AUTOSAR XML (schema 00050)
package /ComponentTypes
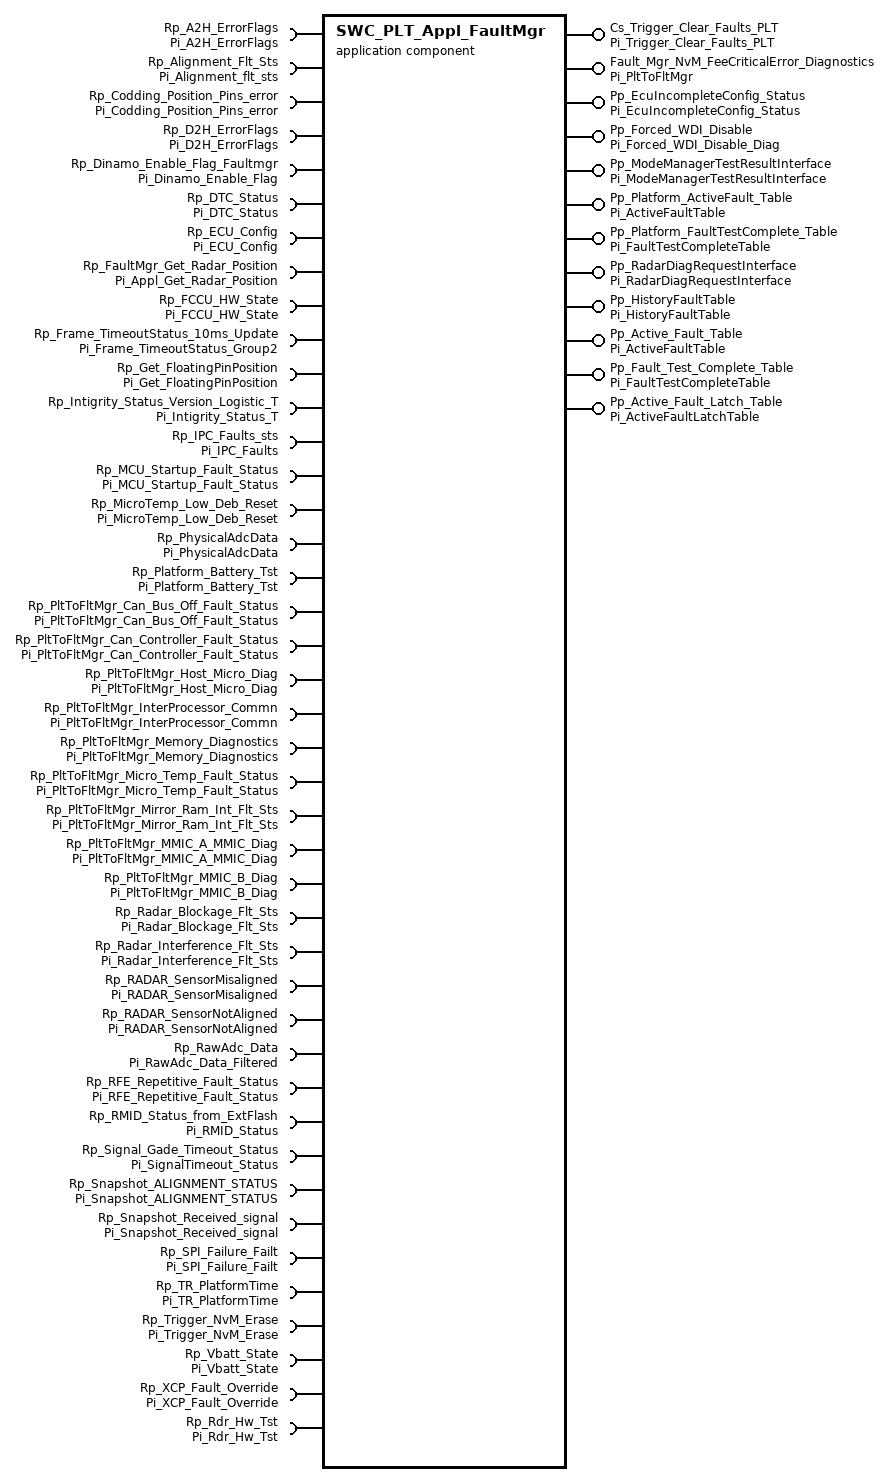
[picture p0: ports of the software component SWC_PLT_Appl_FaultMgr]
  application sw component type SWC_PLT_Appl_FaultMgr
    8 x provide port:
      Cs_Trigger_Clear_Faults_PLT: server-com-spec{operation=Operation, queue-length=1}, provided-interface=Pi_Trigger_Clear_Faults_PLT
      Fault_Mgr_NvM_FeeCriticalError_Diagnostics: server-com-spec{operation=PltToFltMgr_NvM_FeeCriticalError_Diagnostics, queue-length=1}, provided-interface=Pi_PltToFltMgr
      Pp_EcuIncompleteConfig_Status: nonqueued-sender-com-spec{data-element=De_EcuIncompleteConfig_Status, init-value=85}, provided-interface=Pi_EcuIncompleteConfig_Status
      Pp_Forced_WDI_Disable: nonqueued-sender-com-spec{data-element=Forced_WDI_Disable, init-value=0}, provided-interface=Pi_Forced_WDI_Disable_Diag
      Pp_ModeManagerTestResultInterface: nonqueued-sender-com-spec=De_TR_ModeManager, provided-interface=Pi_ModeManagerTestResultInterface
      Pp_Platform_ActiveFault_Table: nonqueued-sender-com-spec{data-element=De_ActiveFaultTable, init-value=constant-reference=C_Fault_T}, provided-interface=Pi_ActiveFaultTable
      Pp_Platform_FaultTestComplete_Table: nonqueued-sender-com-spec{data-element=De_FaultTestCompleteTable, init-value=constant-reference=C_Fault_T}, provided-interface=Pi_FaultTestCompleteTable
      Pp_RadarDiagRequestInterface: nonqueued-sender-com-spec{data-element=De_RadarDiagRequest, init-value=constant-reference=C_RadarDiagRequest_T}, provided-interface=Pi_RadarDiagRequestInterface
    41 x require port:
      Rp_A2H_ErrorFlags: nonqueued-receiver-com-spec{data-element=De_A2H_ErrorFlags, filter=data-filter-type=ALWAYS, init-value=constant-reference=C_A2H_ErrorFlags}, required-interface=Pi_A2H_ErrorFlags
      Rp_Alignment_Flt_Sts: nonqueued-receiver-com-spec{data-element=De_PltToFltMgr_Alignment_Faults, filter=data-filter-type=ALWAYS, init-value=constant-reference=C_PltToFltMgr_Alignment_Faults}, required-interface=Pi_Alignment_flt_sts
      Rp_Codding_Position_Pins_error: nonqueued-receiver-com-spec{data-element=Codding_Position_Pins_error, filter=data-filter-type=ALWAYS, init-value=0}, required-interface=Pi_Codding_Position_Pins_error
      Rp_D2H_ErrorFlags: nonqueued-receiver-com-spec{data-element=De_D2H_ErrorFlags, filter=data-filter-type=ALWAYS, init-value=constant-reference=C_D2H_ErrorFlags}, required-interface=Pi_D2H_ErrorFlags
      Rp_Dinamo_Enable_Flag_Faultmgr: nonqueued-receiver-com-spec{data-element=De_Dinamo_Enable_Flag, filter=data-filter-type=ALWAYS, init-value=85}, required-interface=Pi_Dinamo_Enable_Flag
      Rp_DTC_Status: nonqueued-receiver-com-spec{data-element=De_DTC_Status, filter=data-filter-type=ALWAYS, init-value=0}, required-interface=Pi_DTC_Status
      Rp_ECU_Config: nonqueued-receiver-com-spec{data-element=Dt_ECU_Config, filter=data-filter-type=ALWAYS, init-value=fields=[ECU_Incomplete_Config_Status:0, ECU_Configuration_Updated_Status:0]}, required-interface=Pi_ECU_Config
      Rp_FaultMgr_Get_Radar_Position: nonqueued-receiver-com-spec{data-element=De_ECUPosition, filter=data-filter-type=ALWAYS, init-value=0}, required-interface=Pi_Appl_Get_Radar_Position
      Rp_FCCU_HW_State: nonqueued-receiver-com-spec{data-element=FCCU_HW_State, filter=data-filter-type=ALWAYS, init-value=0}, required-interface=Pi_FCCU_HW_State
      Rp_Frame_TimeoutStatus_10ms_Update: nonqueued-receiver-com-spec{data-element=TimeoutStatus_Group2, filter=data-filter-type=ALWAYS, init-value=constant-reference=C_SignalTimeoutStatus_Group2_T}, required-interface=Pi_Frame_TimeoutStatus_Group2
      Rp_Get_FloatingPinPosition: client-com-spec=FaultStatus, required-interface=Pi_Get_FloatingPinPosition
      Rp_Intigrity_Status_Version_Logistic_T: nonqueued-receiver-com-spec{data-element=Dt_Intigrity_Status_T, filter=data-filter-type=ALWAYS, init-value=0}, required-interface=Pi_Intigrity_Status_T
      Rp_IPC_Faults_sts: nonqueued-receiver-com-spec{data-element=De_IPC_Faults, filter=data-filter-type=ALWAYS, init-value=fields=[IPC_M2D_Crc_Err_Cnt:0, IPC_D2M_Crc_Err_Cnt:0, IPC_D2A_Crc_Err_Cnt:0, IPC_A2M_Crc_Err_Cnt:0]}, required-interface=Pi_IPC_Faults
      Rp_MCU_Startup_Fault_Status: nonqueued-receiver-com-spec{data-element=MCU_Startup_Fault_Status, filter=data-filter-type=ALWAYS, init-value=fields=[Mcu_Startup_Fault_Status:0, Mcu_Repetitive_Reset_Fault_Status:0]}, required-interface=Pi_MCU_Startup_Fault_Status
      Rp_MicroTemp_Low_Deb_Reset: nonqueued-receiver-com-spec{data-element=De_MicroTemp_Low_Deb_Reset, filter=data-filter-type=ALWAYS, init-value=85}, required-interface=Pi_MicroTemp_Low_Deb_Reset
      Rp_PhysicalAdcData: nonqueued-receiver-com-spec{data-element=De_PhysicalAdcData, filter=data-filter-type=ALWAYS, init-value=fields=[Adc_Board_Rev:0, Adc_Batt_Volt:0, Adc_Pos_Gnd_A:0, Adc_Pos_Gnd_B:0, Adc_Pos_Gnd_C:0, Adc_Pos_Gnd_D:0, Adc_Eth_0v9:0, Adc_Rdi_Detect:0, Adc_MMIC_Temp:0, Adc_Mcu_Temp:0, Validity_Flag:0]}, required-interface=Pi_PhysicalAdcData
      Rp_Platform_Battery_Tst: nonqueued-receiver-com-spec{data-element=De_Platform_Battery_Tst, filter=data-filter-type=ALWAYS, init-value=constant-reference=C_Battery_Tst_T}, required-interface=Pi_Platform_Battery_Tst
      Rp_PltToFltMgr_Can_Bus_Off_Fault_Status: nonqueued-receiver-com-spec{data-element=De_PltToFltMgr_Can_Bus_Off_Fault_Status, filter=data-filter-type=ALWAYS, init-value=0}, required-interface=Pi_PltToFltMgr_Can_Bus_Off_Fault_Status
      Rp_PltToFltMgr_Can_Controller_Fault_Status: nonqueued-receiver-com-spec{data-element=De_PltToFltMgr_Can_Controller_Fault_Status, filter=data-filter-type=ALWAYS, init-value=0}, required-interface=Pi_PltToFltMgr_Can_Controller_Fault_Status
      Rp_PltToFltMgr_Host_Micro_Diag: nonqueued-receiver-com-spec{data-element=De_PltToFltMgr_Host_Micro_Diag, filter=data-filter-type=ALWAYS, init-value=constant-reference=C_VldtnToFltMgr_Host_Micro_Diag_T}, required-interface=Pi_PltToFltMgr_Host_Micro_Diag
      Rp_PltToFltMgr_InterProcessor_Commn: nonqueued-receiver-com-spec{data-element=De_PltToFltMgr_InterProcessor_Commn_T, filter=data-filter-type=ALWAYS, init-value=constant-reference=C_VldtnToFltMgr_InterProcessor_Commn_T}, required-interface=Pi_PltToFltMgr_InterProcessor_Commn
      Rp_PltToFltMgr_Memory_Diagnostics: nonqueued-receiver-com-spec{data-element=De_PltToFltMgr_Memory_Diagnostics, filter=data-filter-type=ALWAYS, init-value=constant-reference=C_VldtnToFltMgr_Memory_Diagnostics_T}, required-interface=Pi_PltToFltMgr_Memory_Diagnostics
      Rp_PltToFltMgr_Micro_Temp_Fault_Status: nonqueued-receiver-com-spec{data-element=De_PltToFltMgr_Micro_Temp_Fault_Status, filter=data-filter-type=ALWAYS, init-value=constant-reference=C_VldtnToFltMgr_Micro_Temp_Fault_Status_T}, required-interface=Pi_PltToFltMgr_Micro_Temp_Fault_Status
      Rp_PltToFltMgr_Mirror_Ram_Int_Flt_Sts: nonqueued-receiver-com-spec{data-element=PltToFltMgr_Mirror_Ram_Int_Flt_Sts, filter=data-filter-type=ALWAYS, init-value=0}, required-interface=Pi_PltToFltMgr_Mirror_Ram_Int_Flt_Sts
      Rp_PltToFltMgr_MMIC_A_MMIC_Diag: nonqueued-receiver-com-spec{data-element=De_PltToFltMgr_MMIC_A_MMIC_Diag_T, filter=data-filter-type=ALWAYS, init-value=constant-reference=C_VldtnToFltMgr_MMIC_A_MMIC_Diag_T}, required-interface=Pi_PltToFltMgr_MMIC_A_MMIC_Diag
      Rp_PltToFltMgr_MMIC_B_Diag: nonqueued-receiver-com-spec{data-element=De_PltToFltMgr_MMIC_B_Diag_T, filter=data-filter-type=ALWAYS, init-value=constant-reference=C_VldtnToFltMgr_MMIC_B_Diag_T}, required-interface=Pi_PltToFltMgr_MMIC_B_Diag
      Rp_Radar_Blockage_Flt_Sts: nonqueued-receiver-com-spec{data-element=De_Radar_Blockage_Flt_Sts, filter=data-filter-type=ALWAYS, init-value=constant-reference=C_VldtnToFltMgr_Blockage_Detection_T}, required-interface=Pi_Radar_Blockage_Flt_Sts
      Rp_Radar_Interference_Flt_Sts: nonqueued-receiver-com-spec{data-element=De_Radar_Interference_Flt_Sts, filter=data-filter-type=ALWAYS, init-value=0}, required-interface=Pi_Radar_Interference_Flt_Sts
      Rp_RADAR_SensorMisaligned: nonqueued-receiver-com-spec{data-element=RADAR_SensorMisaligned, filter=data-filter-type=ALWAYS, init-value=0}, required-interface=Pi_RADAR_SensorMisaligned
      Rp_RADAR_SensorNotAligned: nonqueued-receiver-com-spec{data-element=RADAR_SensorNotAligned, filter=data-filter-type=ALWAYS, init-value=0}, required-interface=Pi_RADAR_SensorNotAligned
      Rp_RawAdc_Data: nonqueued-receiver-com-spec{data-element=De_RawAdcData, filter=data-filter-type=ALWAYS, init-value=constant-reference=C_RawAdcDataFilt_T}, required-interface=Pi_RawAdc_Data_Filtered
      Rp_RFE_Repetitive_Fault_Status: nonqueued-receiver-com-spec{data-element=De_RFE_Repetitive_Fault_Status, filter=data-filter-type=ALWAYS, init-value=0}, required-interface=Pi_RFE_Repetitive_Fault_Status
      Rp_RMID_Status_from_ExtFlash: nonqueued-receiver-com-spec{data-element=RMID_Status, filter=data-filter-type=ALWAYS, init-value=0}, required-interface=Pi_RMID_Status
      Rp_Signal_Gade_Timeout_Status: nonqueued-receiver-com-spec{data-element=De_Status, filter=data-filter-type=ALWAYS, init-value=0}, required-interface=Pi_SignalTimeout_Status
      Rp_Snapshot_ALIGNMENT_STATUS: nonqueued-receiver-com-spec{data-element=De_Snapshot_ALIGNMENT_STATUS, filter=data-filter-type=ALWAYS, init-value=constant-reference=C_Snapshot_SupplierCode}, required-interface=Pi_Snapshot_ALIGNMENT_STATUS
      Rp_Snapshot_Received_signal: nonqueued-receiver-com-spec{data-element=De_SnapshotReceivedSignal, filter=data-filter-type=ALWAYS, init-value=constant-reference=C_Snapshot_received_signal_T}, required-interface=Pi_Snapshot_Received_signal
      Rp_SPI_Failure_Failt: nonqueued-receiver-com-spec{data-element=SPI_Failure_Fault, filter=data-filter-type=ALWAYS, init-value=0}, required-interface=Pi_SPI_Failure_Failt
      Rp_TR_PlatformTime: nonqueued-receiver-com-spec{data-element=De_PlatformTime, filter=data-filter-type=ALWAYS, init-value=0}, required-interface=Pi_TR_PlatformTime
      Rp_Trigger_NvM_Erase: client-com-spec=Operation, required-interface=Pi_Trigger_NvM_Erase
      Rp_Vbatt_State: nonqueued-receiver-com-spec{data-element=De_Vbatt_State, filter=data-filter-type=ALWAYS, init-value=0}, required-interface=Pi_Vbatt_State
      Rp_XCP_Fault_Override: nonqueued-receiver-com-spec{data-element=De_XCP_Fault_Override, filter=data-filter-type=ALWAYS, init-value=constant-reference=C_XCP_Fault_Override}, required-interface=Pi_XCP_Fault_Override
    4 x provide port:
      Pp_HistoryFaultTable: nonqueued-sender-com-spec{data-element=De_HistoryFaultTable, init-value=constant-reference=C_Fault_T}, provided-interface=Pi_HistoryFaultTable
      Pp_Active_Fault_Table: nonqueued-sender-com-spec{data-element=De_ActiveFaultTable, init-value=constant-reference=C_Fault_T}, provided-interface=Pi_ActiveFaultTable
      Pp_Fault_Test_Complete_Table: nonqueued-sender-com-spec{data-element=De_FaultTestCompleteTable, init-value=constant-reference=C_Fault_T}, provided-interface=Pi_FaultTestCompleteTable
      Pp_Active_Fault_Latch_Table: nonqueued-sender-com-spec{data-element=De_ActiveFaultLatchTable, init-value=constant-reference=C_Fault_T}, provided-interface=Pi_ActiveFaultLatchTable
    require port Rp_Rdr_Hw_Tst: nonqueued-receiver-com-spec{data-element=De_Rdr_Hw_Tst, handle-out-of-range=DEFAULT, filter=data-filter-type=ALWAYS, init-value=constant-reference=C_Rdr_Hw_Tst_T}, required-interface=Pi_Rdr_Hw_Tst
    behavior SWC_PLT_Appl_FaultMgr_InternalBehavior: handle-termination-and-restart=NO-SUPPORT
      5 x timing event, all with period=0.05:
        TMT_RE_Alignment_Diagnostics_50ms: start-on-event=RE_PLT_Fault_Mgr_Alignment_Diagnostics_50ms
        TMT_RE_Fault_Mgr_Battery_Fault_Tests: start-on-event=RE_PLT_Fault_Mgr_Battery_Fault_Tests_50ms
        TMT_RE_Fault_Mgr_Can_Bus_Off_Fault_Test: start-on-event=RE_PLT_Fault_Mgr_Can_Bus_Off_Fault_Test_50ms
        TMT_RE_General_Diagnostics_50ms: start-on-event=RE_PLT_Fault_Mgr_General_Diagnostics_50ms
        TMT_RE_Fault_Mgr_Host_Microcontroller_Tests: start-on-event=RE_PLT_Fault_Mgr_Host_Microcontroller_Tests_50ms
      init event SWC_Appl_Diag_InitEvent: start-on-event=RE_PLT_Fault_Mgr_Init
      9 x timing event:
        TMT_RE_Fault_Mgr_Interprocessor_Comm: start-on-event=RE_PLT_Fault_Mgr_Interprocessor_Comm_50ms, period=0.05
        TMT_RE_FaultMgr_Main_10ms: start-on-event=RE_PLT_Fault_Mgr_Main_10ms, period=0.01
        TMT_RE_Diag_Main_50ms: start-on-event=RE_PLT_Fault_Mgr_Main_50ms, period=0.05
        TMT_RE_Fault_Mgr_Memory_Diagnostics: start-on-event=RE_PLT_Fault_Mgr_Memory_Diagnostics_50ms, period=0.05
        TMT_RE_Fault_Mgr_Microprocessor_Temp_Tests: start-on-event=RE_PLT_Fault_Mgr_Microprocessor_Temp_Tests_50ms, period=0.05
        TMT_RE_Fault_Mgr_Radar_Blockage_Detection_Test: start-on-event=RE_PLT_Fault_Mgr_Radar_Blockage_Detection_Test_50ms, period=0.05
        TMT_RE_Fault_Mgr_Radar_Hardware_Tests: start-on-event=RE_PLT_Fault_Mgr_Radar_Hardware_Tests_50ms, period=0.05
        TMT_RE_Fault_Mgr_Dolphin_Chip_Diagnostics: start-on-event=RE_PLT_Fault_Mgr_Radar_Transceiver_Diagnostics_50ms, period=0.05
        TMT_RE_Watchdog_Diagnostics_50ms: start-on-event=RE_PLT_Fault_Mgr_Watchdog_Diagnostics_50ms, period=0.05
      port-api-options:
        enable-take-address=false, error-handling=NO-TRANSFORMER-ERROR-HANDLING, indirect-api=false, port=Cs_Trigger_Clear_Faults_PLT
        enable-take-address=false, error-handling=NO-TRANSFORMER-ERROR-HANDLING, indirect-api=false, port=Pp_Forced_WDI_Disable
        enable-take-address=false, error-handling=NO-TRANSFORMER-ERROR-HANDLING, indirect-api=false, port=Rp_A2H_ErrorFlags
        enable-take-address=false, error-handling=NO-TRANSFORMER-ERROR-HANDLING, indirect-api=false, port=Rp_Codding_Position_Pins_error
        enable-take-address=false, error-handling=NO-TRANSFORMER-ERROR-HANDLING, indirect-api=false, port=Rp_D2H_ErrorFlags
        enable-take-address=false, error-handling=NO-TRANSFORMER-ERROR-HANDLING, indirect-api=false, port=Rp_ECU_Config
        enable-take-address=false, error-handling=NO-TRANSFORMER-ERROR-HANDLING, indirect-api=false, port=Rp_FCCU_HW_State
        enable-take-address=false, error-handling=NO-TRANSFORMER-ERROR-HANDLING, indirect-api=false, port=Rp_Frame_TimeoutStatus_10ms_Update
        enable-take-address=false, error-handling=NO-TRANSFORMER-ERROR-HANDLING, indirect-api=false, port=Rp_PhysicalAdcData
        enable-take-address=false, error-handling=NO-TRANSFORMER-ERROR-HANDLING, indirect-api=false, port=Rp_RADAR_SensorMisaligned
        enable-take-address=false, error-handling=NO-TRANSFORMER-ERROR-HANDLING, indirect-api=false, port=Rp_RADAR_SensorNotAligned
        enable-take-address=false, error-handling=NO-TRANSFORMER-ERROR-HANDLING, indirect-api=false, port=Rp_RawAdc_Data
        enable-take-address=false, error-handling=NO-TRANSFORMER-ERROR-HANDLING, indirect-api=false, port=Rp_RMID_Status_from_ExtFlash
        enable-take-address=false, error-handling=NO-TRANSFORMER-ERROR-HANDLING, indirect-api=false, port=Rp_Snapshot_ALIGNMENT_STATUS
        enable-take-address=false, error-handling=NO-TRANSFORMER-ERROR-HANDLING, indirect-api=false, port=Rp_Snapshot_Received_signal
        enable-take-address=false, error-handling=NO-TRANSFORMER-ERROR-HANDLING, indirect-api=false, port=Rp_SPI_Failure_Failt
      15 x runnable:
        RE_PLT_Fault_Mgr_Alignment_Diagnostics_50ms
          data-receive-point-by-arguments:
            4 x access:
              REC_Rp_Alignment_flt_sts_De_PltToFltMgr_Alignment_Faults: accessed-variable=Rp_Alignment_Flt_Sts.De_PltToFltMgr_Alignment_Faults
              REC_Rp_Codding_Position_Pins_error_Codding_Position_Pins_error: accessed-variable=Rp_Codding_Position_Pins_error.Codding_Position_Pins_error
              REC_Rp_RADAR_SensorMisaligned_RADAR_SensorMisaligned: accessed-variable=Rp_RADAR_SensorMisaligned.RADAR_SensorMisaligned
              REC_Rp_RADAR_SensorNotAligned_RADAR_SensorNotAligned: accessed-variable=Rp_RADAR_SensorNotAligned.RADAR_SensorNotAligned
        RE_PLT_Fault_Mgr_Battery_Fault_Tests_50ms
          data-receive-point-by-arguments:
            access REC_Rp_Validation_Battery_Tst_De_Validation_Battery_Tst: accessed-variable=Rp_Platform_Battery_Tst.De_Platform_Battery_Tst
        RE_PLT_Fault_Mgr_Can_Bus_Off_Fault_Test_50ms
          data-receive-point-by-arguments:
            access REC_Rp_PltToFltMgr_Can_Bus_Off_Fault_Status_De_PltToFltMgr_Can_Bus_Off_Fault_Status: accessed-variable=Rp_PltToFltMgr_Can_Bus_Off_Fault_Status.De_PltToFltMgr_Can_Bus_Off_Fault_Status
        RE_PLT_Fault_Mgr_General_Diagnostics_50ms
          data-receive-point-by-arguments:
            4 x access:
              REC_Rp_Dinamo_Enable_Flag_Faultmgr_De_Dinamo_Enable_Flag: accessed-variable=Rp_Dinamo_Enable_Flag_Faultmgr.De_Dinamo_Enable_Flag
              REC_Rp_DTC_Status_De_DTC_Status: accessed-variable=Rp_DTC_Status.De_DTC_Status
              REC_Rp_ECU_Config_Dt_ECU_Config: accessed-variable=Rp_ECU_Config.Dt_ECU_Config
              REC_Rp_Intigrity_Status_Version_Logistic_T_Dt_Intigrity_Status_T: accessed-variable=Rp_Intigrity_Status_Version_Logistic_T.Dt_Intigrity_Status_T
          data-send-points:
            access SEND_Pp_EcuIncompleteConfig_Status_De_EcuIncompleteConfig_Status: accessed-variable=Pp_EcuIncompleteConfig_Status.De_EcuIncompleteConfig_Status
            access SEND_Pp_Platform_ActiveFault_Table_De_ActiveFaultTable: accessed-variable=Pp_Platform_ActiveFault_Table.De_ActiveFaultTable
            access SEND_Pp_Platform_FaultTestComplete_Table_De_FaultTestCompleteTable: accessed-variable=Pp_Platform_FaultTestComplete_Table.De_FaultTestCompleteTable
        RE_PLT_Fault_Mgr_Host_Microcontroller_Tests_50ms
          data-receive-point-by-arguments:
            access REC_Rp_VldtnToFltMgr_Host_Micro_Diag_De_VldtnToFltMgr_Host_Micro_Diag: accessed-variable=Rp_PltToFltMgr_Host_Micro_Diag.De_PltToFltMgr_Host_Micro_Diag
        RE_PLT_Fault_Mgr_Init  # This runnable will initialize all the static variables of this SWC
          data-receive-point-by-arguments:
            4 x access:
              REC_Rp_FaultMgr_Get_Radar_Position_De_ECUPosition: accessed-variable=Rp_FaultMgr_Get_Radar_Position.De_ECUPosition
              REC_Rp_MCU_Startup_Fault_Status_MCU_Startup_Fault_Status: accessed-variable=Rp_MCU_Startup_Fault_Status.MCU_Startup_Fault_Status
              REC_Rp_RFE_Repetitive_Fault_Status_De_RFE_Repetitive_Fault_Status: accessed-variable=Rp_RFE_Repetitive_Fault_Status.De_RFE_Repetitive_Fault_Status
              REC_Rp_VldtnToFltMgr_Can_Controller_Fault_Status_De_VldtnToFltMgr_Can_Controller_Fault_Status: accessed-variable=Rp_PltToFltMgr_Can_Controller_Fault_Status.De_PltToFltMgr_Can_Controller_Fault_Status
        RE_PLT_Fault_Mgr_Interprocessor_Comm_50ms
          data-receive-point-by-arguments:
            access REC_Rp_IPC_Faults_sts_De_IPC_Faults: accessed-variable=Rp_IPC_Faults_sts.De_IPC_Faults
            access REC_Rp_VldtnToFltMgr_InterProcessor_Commn_De_VldtnToFltMgr_InterProcessor_Commn_50ms_T: accessed-variable=Rp_PltToFltMgr_InterProcessor_Commn.De_PltToFltMgr_InterProcessor_Commn_T
        RE_PLT_Fault_Mgr_Main_10ms  # This function will be used to do timeout of the Missing signal with periodicity 10 and 20ms Signals are as fallows: 1. ATCU_A108C_FD 2. FWS_R3C_FD 3. ADAS_A109_FD 4. VDC_A116C_FD 5. VDC_A117C_FD 6. STRG_A1C_FD
          data-receive-point-by-arguments:
            access REC_Rp_Frame_TimeoutStatus_10ms_Update_TimeoutStatus_Group2: accessed-variable=Rp_Frame_TimeoutStatus_10ms_Update.TimeoutStatus_Group2
            access REC_Rp_Signal_Gade_Timeout_Status_De_Status: accessed-variable=Rp_Signal_Gade_Timeout_Status.De_Status
          data-send-points:
            access SEND_Pp_ModeManagerTestResultInterface_De_TR_ModeManager: accessed-variable=Pp_ModeManagerTestResultInterface.De_TR_ModeManager
            access SEND_Pp_RadarDiagRequestInterface_De_RadarDiagRequest: accessed-variable=Pp_RadarDiagRequestInterface.De_RadarDiagRequest
        RE_PLT_Fault_Mgr_Main_50ms  # All the functionalities which are related to 50ms diagnostics shall be run here
          data-receive-point-by-arguments:
            8 x access:
              REC_Pi_A2H_ErrorFlags_De_A2H_ErrorFlags: accessed-variable=Rp_A2H_ErrorFlags.De_A2H_ErrorFlags
              REC_Rp_D2H_ErrorFlags_De_D2H_ErrorFlags: accessed-variable=Rp_D2H_ErrorFlags.De_D2H_ErrorFlags
              REC_Rp_FCCU_HW_State_FCCU_HW_State: accessed-variable=Rp_FCCU_HW_State.FCCU_HW_State
              REC_Rp_PhysicalAdcData_De_PhysicalAdcData: accessed-variable=Rp_PhysicalAdcData.De_PhysicalAdcData
              REC_Rp_RawAdc_Data_De_RawAdcData: accessed-variable=Rp_RawAdc_Data.De_RawAdcData
              REC_Rp_RMID_Status_from_ExtFlash_RMID_Status: accessed-variable=Rp_RMID_Status_from_ExtFlash.RMID_Status
              REC_Rp_SPI_Failure_Failt_SPI_Failure_Fault: accessed-variable=Rp_SPI_Failure_Failt.SPI_Failure_Fault
              REC_Rp_XCP_Fault_Override_De_XCP_Fault_Override: accessed-variable=Rp_XCP_Fault_Override.De_XCP_Fault_Override
          data-send-points:
            5 x access:
              SEND_Pp_Forced_WDI_Disable_Forced_WDI_Disable: accessed-variable=Pp_Forced_WDI_Disable.Forced_WDI_Disable
              SEND_Pp_Active_Fault_Table_De_ActiveFaultTable: accessed-variable=Pp_Active_Fault_Table.De_ActiveFaultTable
              SEND_Pp_Fault_Test_Complete_Table_De_FaultTestCompleteTable: accessed-variable=Pp_Fault_Test_Complete_Table.De_FaultTestCompleteTable
              SEND_Pp_HistoryFaultTable_De_HistoryFaultTable: accessed-variable=Pp_HistoryFaultTable.De_HistoryFaultTable
              SEND_Pp_Active_Fault_Latch_Table_De_ActiveFaultLatchTable: accessed-variable=Pp_Active_Fault_Latch_Table.De_ActiveFaultLatchTable
          sync call SC_Rp_Get_FloatingPinPosition_FaultStatus: operation=Rp_Get_FloatingPinPosition.FaultStatus
          sync call SC_Rp_Trigger_NvM_Erase_Operation: operation=Rp_Trigger_NvM_Erase.Operation
        RE_PLT_Fault_Mgr_Memory_Diagnostics_50ms
          data-receive-point-by-arguments:
            access REC_Rp_PltToFltMgr_Mirror_Ram_Int_Flt_Sts_PltToFltMgr_Mirror_Ram_Int_Flt_Sts: accessed-variable=Rp_PltToFltMgr_Mirror_Ram_Int_Flt_Sts.PltToFltMgr_Mirror_Ram_Int_Flt_Sts
            access REC_Rp_VldtnToFltMgr_Memory_Diagnostics_De_VldtnToFltMgr_Memory_Diagnostics: accessed-variable=Rp_PltToFltMgr_Memory_Diagnostics.De_PltToFltMgr_Memory_Diagnostics
        RE_PLT_Fault_Mgr_Microprocessor_Temp_Tests_50ms
          data-receive-point-by-arguments:
            access REC_Rp_MicroTemp_Low_Deb_Reset_De_MicroTemp_Low_Deb_Reset: accessed-variable=Rp_MicroTemp_Low_Deb_Reset.De_MicroTemp_Low_Deb_Reset
            access REC_Rp_VldtnToFltMgr_Micro_Temp_Fault_Status_De_VldtnToFltMgr_Micro_Temp_Fault_Status: accessed-variable=Rp_PltToFltMgr_Micro_Temp_Fault_Status.De_PltToFltMgr_Micro_Temp_Fault_Status
        RE_PLT_Fault_Mgr_Radar_Blockage_Detection_Test_50ms
          data-receive-point-by-arguments:
            access REC_Rp_Radar_Blockage_Flt_Sts_De_Radar_Blockage_Flt_Sts: accessed-variable=Rp_Radar_Blockage_Flt_Sts.De_Radar_Blockage_Flt_Sts
            access REC_Rp_Radar_Interference_Flt_Sts_De_Radar_Interference_Flt_Sts: accessed-variable=Rp_Radar_Interference_Flt_Sts.De_Radar_Interference_Flt_Sts
        RE_PLT_Fault_Mgr_Radar_Hardware_Tests_50ms
          data-receive-point-by-arguments:
            access REC_Rp_Rdr_Hw_Tst_De_Rdr_Hw_Tst: accessed-variable=Rp_Rdr_Hw_Tst.De_Rdr_Hw_Tst
            access REC_Rp_TR_PlatformTime_De_TR_PlatformTime: accessed-variable=Rp_TR_PlatformTime.De_PlatformTime
        RE_PLT_Fault_Mgr_Radar_Transceiver_Diagnostics_50ms
          data-receive-point-by-arguments:
            access REC_Rp_PltToFltMgr_MMIC_B_Diag_De_PltToFltMgr_MMIC_B_Diag_T: accessed-variable=Rp_PltToFltMgr_MMIC_B_Diag.De_PltToFltMgr_MMIC_B_Diag_T
            access REC_Rp_VldtnToFltMgr_Dolphin_Diag_De_VldtnToFltMgr_Dolphin_Diag: accessed-variable=Rp_PltToFltMgr_MMIC_A_MMIC_Diag.De_PltToFltMgr_MMIC_A_MMIC_Diag_T
        RE_PLT_Fault_Mgr_Watchdog_Diagnostics_50ms
  swc implementation SWC_PLT_Appl_FaultMgr_Implementation: behavior=SWC_PLT_Appl_FaultMgr_InternalBehavior
    code-descriptors:
      code Default: artifact-descriptors=autosar-engineering-object=category=SWSRC
